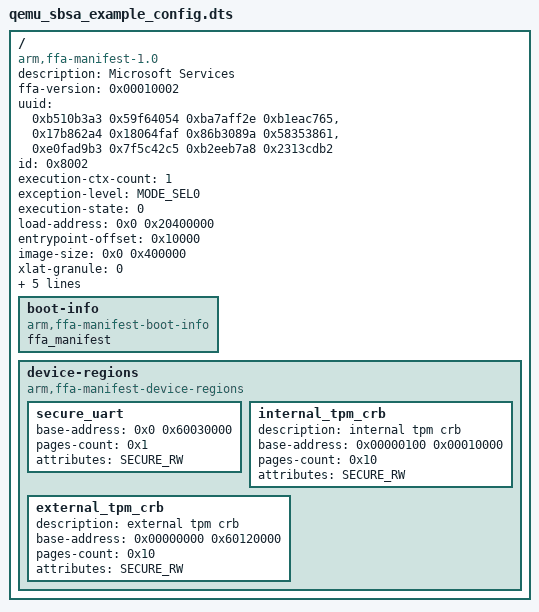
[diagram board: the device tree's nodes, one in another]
/*
 * Copyright (c) 2020-21, ARM Limited and Contributors. All rights reserved.
 *
 * SPDX-License-Identifier: BSD-3-Clause
 */

/dts-v1/;

/ {
#define MODE_SEL0	(0x1)
#define MODE_SEL1	(0x2)

#define SECURE_RO 0x1
#define SECURE_RW 0x3
#define SECURE_EXECUTE_RO 0x5
#define SECURE_EXECUTE_RW 0x7
#define NON_SECURE_RO 0x9
#define NON_SECURE_RW 0xB
#define NON_SECURE_EXECUTE_RO 0xD
#define NONSECURE_EXECUTE_RW 0xF
	/*
	 * FF-A compatible Secure Partition Manager parses the
	 * config file and fetch the following booting arguments to
	 * pass on to the StandAloneMM(StMM) Secure Partition.
	 */
	compatible = "arm,ffa-manifest-1.0";

	description = "Microsoft Services";
	ffa-version = <0x00010002>; /* 31:16 - Major, 15:0 - Minor */
	uuid = <0xb510b3a3 0x59f64054 0xba7aff2e 0xb1eac765>, <0x17b862a4 0x18064faf 0x86b3089a 0x58353861>, <0xe0fad9b3 0x7f5c42c5 0xb2eeb7a8 0x2313cdb2>;
	id = <0x8002>;
	execution-ctx-count = <1>;
	exception-level = <MODE_SEL0>; /* SEL0*/
	execution-state = <0>; /* AArch64*/
	load-address = <0x0 0x20400000>;
	entrypoint-offset = <0x10000>;
	image-size = <0x0 0x400000>;
	xlat-granule = <0>; /* 4KiB */
	boot-order = <1>;
	messaging-method = <0x603>; /* Direct request/response supported. */
	ns-interrupts-action = <2>; /* Non-secure interrupt is signaled */
	notification-support; /* Support receipt of notifications. */
	gp-register-num = <0>;

	boot-info {
		compatible = "arm,ffa-manifest-boot-info";
		ffa_manifest;
	};

	device-regions {
		compatible = "arm,ffa-manifest-device-regions";

		/*
		 * Secure UART region.
		 */
		secure_uart {
			base-address = <0x0 0x60030000>;
			pages-count = <0x1>;
			attributes = <SECURE_RW>;
		};

		internal_tpm_crb {
			description = "internal tpm crb";
			base-address = <0x00000100 0x00010000>;
			pages-count = <0x10>;
			attributes = <SECURE_RW>;
		};

		external_tpm_crb {
			description = "external tpm crb";
			base-address = <0x00000000 0x60120000>;
			pages-count = <0x10>;
			attributes = <SECURE_RW>;
		};
	};
};
